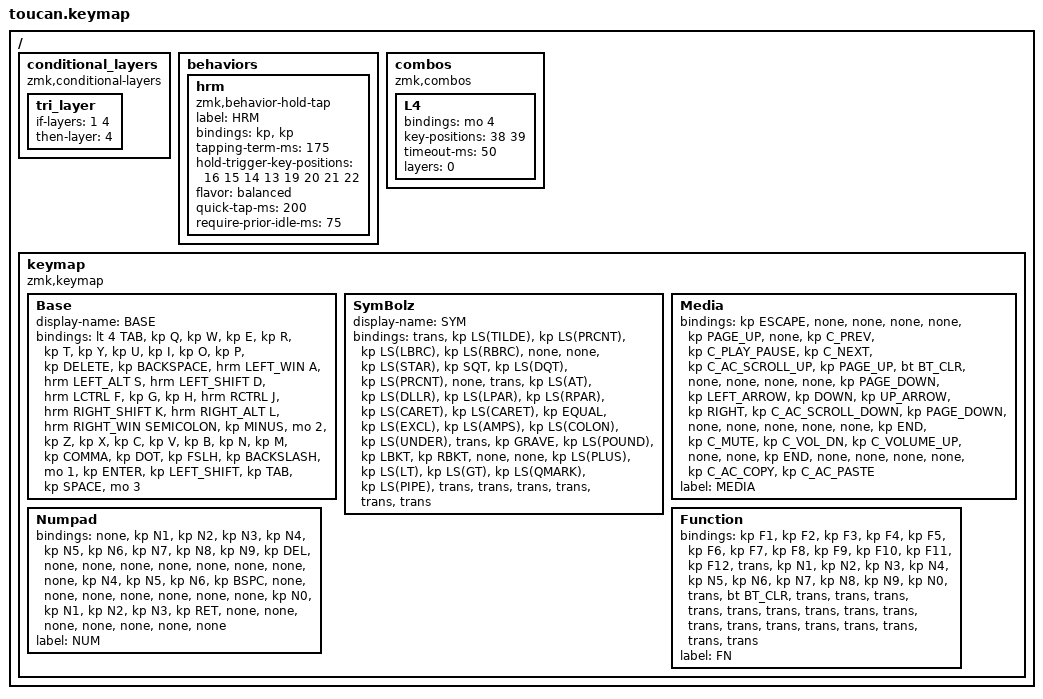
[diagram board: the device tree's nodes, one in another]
#include <behaviors.dtsi>
#include <dt-bindings/zmk/bt.h>
#include <dt-bindings/zmk/keys.h>

#define BASE 0
#define NAV  1
#define SYM  2
#define ADJ  3

/ {
    conditional_layers {
        compatible = "zmk,conditional-layers";

        tri_layer {
            if-layers = <1 4>;
            then-layer = <4>;
        };
    };

    behaviors {
        hrm: hrm {
            compatible = "zmk,behavior-hold-tap";
            label = "HRM";
            bindings = <&kp>, <&kp>;

            #binding-cells = <2>;
            tapping-term-ms = <175>;
            hold-trigger-key-positions = <16 15 14 13 19 20 21 22>;
            flavor = "balanced";
            quick-tap-ms = <200>;
            require-prior-idle-ms = <75>;
        };
    };

    combos {
        compatible = "zmk,combos";

        L4 {
            bindings = <&mo 4>;
            key-positions = <38 39>;
            timeout-ms = <50>;
            layers = <0>;
        };
    };

    keymap {
        compatible = "zmk,keymap";

        Base {
            display-name = "BASE";
            bindings = <
&lt 4 TAB  &kp Q  &kp W  &kp E  &kp R  &kp T  &kp Y  &kp U  &kp I  &kp O  &kp P  &kp DELETE  &kp BACKSPACE  &hrm LEFT_WIN A  &hrm LEFT_ALT S  &hrm LEFT_SHIFT D  &hrm LCTRL F  &kp G  &kp H  &hrm RCTRL J  &hrm RIGHT_SHIFT K  &hrm RIGHT_ALT L  &hrm RIGHT_WIN SEMICOLON  &kp MINUS  &mo 2  &kp Z  &kp X  &kp C  &kp V  &kp B  &kp N  &kp M  &kp COMMA  &kp DOT  &kp FSLH  &kp BACKSLASH  &mo 1  &kp ENTER  &kp LEFT_SHIFT  &kp TAB  &kp SPACE  &mo 3
            >;
        };

        SymBolz {
            display-name = "SYM";
            bindings = <
&trans  &kp LS(TILDE)  &kp LS(PRCNT)  &kp LS(LBRC)  &kp LS(RBRC)  &none  &none  &kp LS(STAR)  &kp SQT  &kp LS(DQT)  &kp LS(PRCNT)  &none  &trans  &kp LS(AT)  &kp LS(DLLR)  &kp LS(LPAR)  &kp LS(RPAR)  &kp LS(CARET)  &kp LS(CARET)  &kp EQUAL  &kp LS(EXCL)  &kp LS(AMPS)  &kp LS(COLON)  &kp LS(UNDER)  &trans  &kp GRAVE  &kp LS(POUND)  &kp LBKT  &kp RBKT  &none  &none  &kp LS(PLUS)  &kp LS(LT)  &kp LS(GT)  &kp LS(QMARK)  &kp LS(PIPE)  &trans  &trans  &trans  &trans  &trans  &trans
            >;
        };

        Media {
            bindings = <
&kp ESCAPE  &none  &none  &none  &none  &kp PAGE_UP  &none  &kp C_PREV  &kp C_PLAY_PAUSE  &kp C_NEXT  &kp C_AC_SCROLL_UP  &kp PAGE_UP  &bt BT_CLR  &none  &none  &none  &none  &kp PAGE_DOWN  &kp LEFT_ARROW  &kp DOWN  &kp UP_ARROW  &kp RIGHT  &kp C_AC_SCROLL_DOWN  &kp PAGE_DOWN  &none  &none  &none  &none  &none  &kp END  &kp C_MUTE  &kp C_VOL_DN  &kp C_VOLUME_UP  &none  &none  &kp END  &none  &none  &none  &none  &kp C_AC_COPY  &kp C_AC_PASTE
            >;

            label = "MEDIA";
        };

        Numpad {
            bindings = <
&none  &kp N1  &kp N2  &kp N3  &kp N4  &kp N5  &kp N6  &kp N7  &kp N8  &kp N9  &kp DEL  &none  &none  &none  &none  &none  &none  &none  &none  &kp N4  &kp N5  &kp N6  &kp BSPC  &none  &none  &none  &none  &none  &none  &none  &kp N0  &kp N1  &kp N2  &kp N3  &kp RET  &none  &none  &none  &none  &none  &none  &none
            >;

            label = "NUM";
        };

        Function {
            bindings = <
&kp F1  &kp F2  &kp F3  &kp F4  &kp F5  &kp F6  &kp F7  &kp F8  &kp F9  &kp F10  &kp F11  &kp F12  &trans  &kp N1  &kp N2  &kp N3  &kp N4  &kp N5  &kp N6  &kp N7  &kp N8  &kp N9  &kp N0  &trans  &bt BT_CLR  &trans  &trans  &trans  &trans  &trans  &trans  &trans  &trans  &trans  &trans  &trans  &trans  &trans  &trans  &trans  &trans  &trans
            >;

            label = "FN";
        };
    };
};
